AUTOSAR XML (schema 4-0-3)
standard types defined: uint8, Boolean, UInt16, UInt32
package /AUTOSAR_Platform/DataConstrs
  range DC_Boolean: raw 0..1
  range DC_UInt16: raw 0..65535
package /DataTypes/Units
  unit NoUnit1: display-name=NoUnit, factor-si-to-unit=1, offset-si-to-unit=0
package /PATAC/Facility/DataTypes/Implementation
  compu method COMPU_Boolean: 0=FALSE, 1=TRUE
  unit NoUnit: factor-si-to-unit=1, offset-si-to-unit=0
package /PATAC/MSM/ComponentTypes
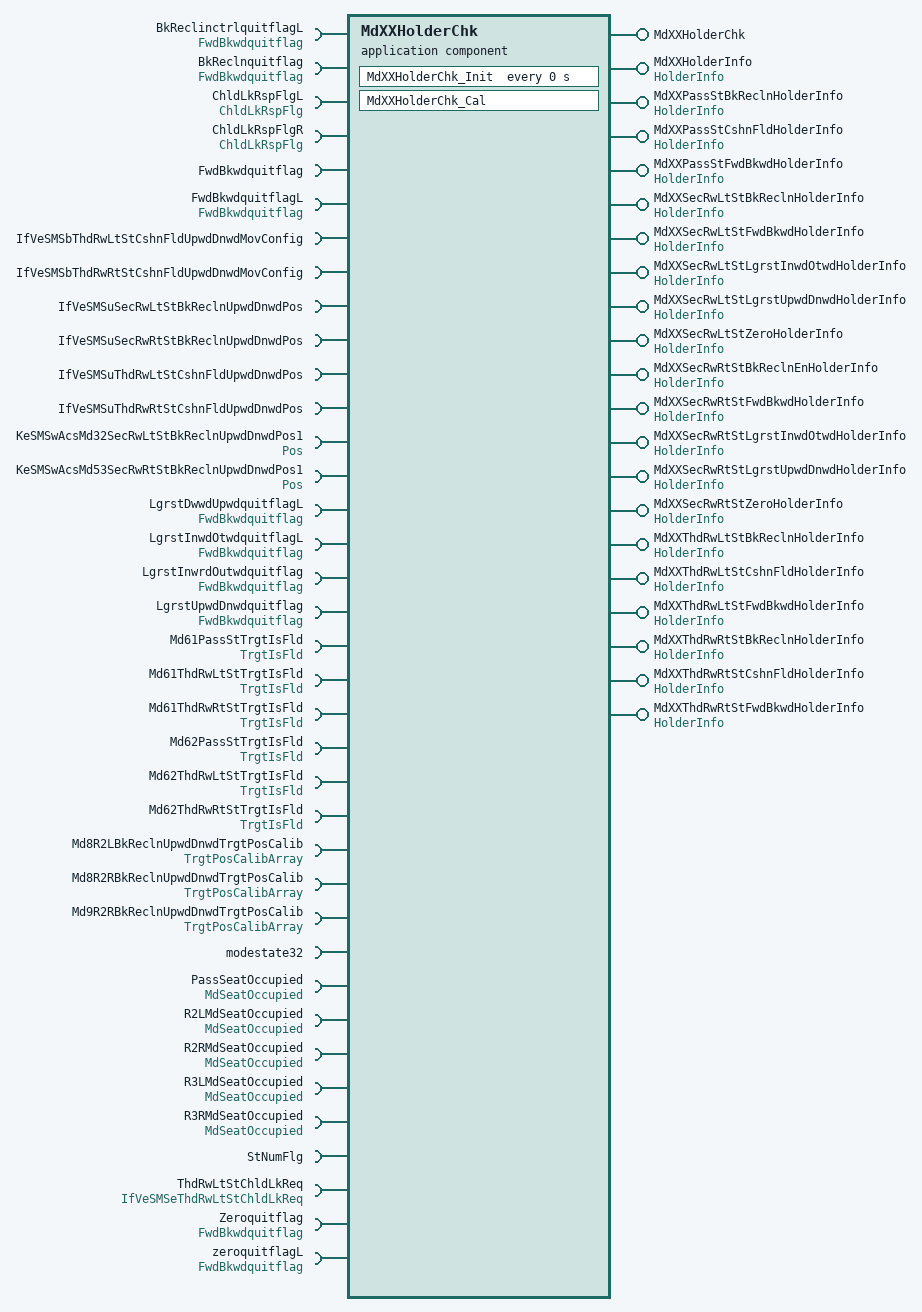
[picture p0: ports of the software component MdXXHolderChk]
  application sw component type MdXXHolderChk
    21 x provide port:
      MdXXHolderChk: server-com-spec{operation=Cal, queue-length=1}, provided-interface=MdXXHolderChk
      MdXXHolderInfo: nonqueued-sender-com-spec{data-element=HolderInfo/Val, init-value=0}, provided-interface=HolderInfo
      MdXXPassStBkReclnHolderInfo: nonqueued-sender-com-spec{data-element=HolderInfo/Val, init-value=0}, provided-interface=HolderInfo
      MdXXPassStCshnFldHolderInfo: nonqueued-sender-com-spec{data-element=HolderInfo/Val, init-value=0}, provided-interface=HolderInfo
      MdXXPassStFwdBkwdHolderInfo: nonqueued-sender-com-spec{data-element=HolderInfo/Val, init-value=0}, provided-interface=HolderInfo
      MdXXSecRwLtStBkReclnHolderInfo: nonqueued-sender-com-spec{data-element=HolderInfo/Val, init-value=0}, provided-interface=HolderInfo
      MdXXSecRwLtStFwdBkwdHolderInfo: nonqueued-sender-com-spec{data-element=HolderInfo/Val, init-value=0}, provided-interface=HolderInfo
      MdXXSecRwLtStLgrstInwdOtwdHolderInfo: nonqueued-sender-com-spec{data-element=HolderInfo/Val, init-value=0}, provided-interface=HolderInfo
      MdXXSecRwLtStLgrstUpwdDnwdHolderInfo: nonqueued-sender-com-spec{data-element=HolderInfo/Val, init-value=0}, provided-interface=HolderInfo
      MdXXSecRwLtStZeroHolderInfo: nonqueued-sender-com-spec{data-element=HolderInfo/Val, init-value=0}, provided-interface=HolderInfo
      MdXXSecRwRtStBkReclnEnHolderInfo: nonqueued-sender-com-spec{data-element=HolderInfo/Val, init-value=0}, provided-interface=HolderInfo
      MdXXSecRwRtStFwdBkwdHolderInfo: nonqueued-sender-com-spec{data-element=HolderInfo/Val, init-value=0}, provided-interface=HolderInfo
      MdXXSecRwRtStLgrstInwdOtwdHolderInfo: nonqueued-sender-com-spec{data-element=HolderInfo/Val, init-value=0}, provided-interface=HolderInfo
      MdXXSecRwRtStLgrstUpwdDnwdHolderInfo: nonqueued-sender-com-spec{data-element=HolderInfo/Val, init-value=0}, provided-interface=HolderInfo
      MdXXSecRwRtStZeroHolderInfo: nonqueued-sender-com-spec{data-element=HolderInfo/Val, init-value=0}, provided-interface=HolderInfo
      MdXXThdRwLtStBkReclnHolderInfo: nonqueued-sender-com-spec{data-element=HolderInfo/Val, init-value=0}, provided-interface=HolderInfo
      MdXXThdRwLtStCshnFldHolderInfo: nonqueued-sender-com-spec{data-element=HolderInfo/Val, init-value=0}, provided-interface=HolderInfo
      MdXXThdRwLtStFwdBkwdHolderInfo: nonqueued-sender-com-spec{data-element=HolderInfo/Val, init-value=0}, provided-interface=HolderInfo
      MdXXThdRwRtStBkReclnHolderInfo: nonqueued-sender-com-spec{data-element=HolderInfo/Val, init-value=0}, provided-interface=HolderInfo
      MdXXThdRwRtStCshnFldHolderInfo: nonqueued-sender-com-spec{data-element=HolderInfo/Val, init-value=0}, provided-interface=HolderInfo
      MdXXThdRwRtStFwdBkwdHolderInfo: nonqueued-sender-com-spec{data-element=HolderInfo/Val, init-value=0}, provided-interface=HolderInfo
    37 x require port:
      BkReclinctrlquitflagL: nonqueued-receiver-com-spec{data-element=FwdBkwdquitflag/Val, filter=data-filter-type=ALWAYS, init-value=0}, required-interface=FwdBkwdquitflag
      BkReclnquitflag: nonqueued-receiver-com-spec{data-element=FwdBkwdquitflag/Val, filter=data-filter-type=ALWAYS, init-value=0}, required-interface=FwdBkwdquitflag
      ChldLkRspFlgL: nonqueued-receiver-com-spec{data-element=ChldLkRspFlg/Val, filter=data-filter-type=ALWAYS, init-value=0}, required-interface=ChldLkRspFlg
      ChldLkRspFlgR: nonqueued-receiver-com-spec{data-element=ChldLkRspFlg/Val, filter=data-filter-type=ALWAYS, init-value=0}, required-interface=ChldLkRspFlg
      FwdBkwdquitflag: nonqueued-receiver-com-spec{data-element=FwdBkwdquitflag/Val, filter=data-filter-type=ALWAYS, init-value=0}, required-interface=FwdBkwdquitflag
      FwdBkwdquitflagL: nonqueued-receiver-com-spec{data-element=FwdBkwdquitflag/Val, filter=data-filter-type=ALWAYS, init-value=0}, required-interface=FwdBkwdquitflag
      IfVeSMSbThdRwLtStCshnFldUpwdDnwdMovConfig: nonqueued-receiver-com-spec{data-element=IfVeSMSbThdRwLtStCshnFldUpwdDnwdMovConfig/Val, filter=data-filter-type=ALWAYS, init-value=0}, required-interface=IfVeSMSbThdRwLtStCshnFldUpwdDnwdMovConfig
      IfVeSMSbThdRwRtStCshnFldUpwdDnwdMovConfig: nonqueued-receiver-com-spec{data-element=IfVeSMSbThdRwRtStCshnFldUpwdDnwdMovConfig/Val, filter=data-filter-type=ALWAYS, init-value=0}, required-interface=IfVeSMSbThdRwRtStCshnFldUpwdDnwdMovConfig
      IfVeSMSuSecRwLtStBkReclnUpwdDnwdPos: nonqueued-receiver-com-spec{data-element=IfVeSMSuSecRwLtStBkReclnUpwdDnwdPos/Val, filter=data-filter-type=ALWAYS, init-value=0}, required-interface=IfVeSMSuSecRwLtStBkReclnUpwdDnwdPos
      IfVeSMSuSecRwRtStBkReclnUpwdDnwdPos: nonqueued-receiver-com-spec{data-element=IfVeSMSuSecRwRtStBkReclnUpwdDnwdPos/Val, filter=data-filter-type=ALWAYS, init-value=0}, required-interface=IfVeSMSuSecRwRtStBkReclnUpwdDnwdPos
      IfVeSMSuThdRwLtStCshnFldUpwdDnwdPos: nonqueued-receiver-com-spec{data-element=IfVeSMSuThdRwLtStCshnFldUpwdDnwdPos/Val, filter=data-filter-type=ALWAYS, init-value=0}, required-interface=IfVeSMSuThdRwLtStCshnFldUpwdDnwdPos
      IfVeSMSuThdRwRtStCshnFldUpwdDnwdPos: nonqueued-receiver-com-spec{data-element=IfVeSMSuThdRwRtStCshnFldUpwdDnwdPos/Val, filter=data-filter-type=ALWAYS, init-value=0}, required-interface=IfVeSMSuThdRwRtStCshnFldUpwdDnwdPos
      KeSMSwAcsMd32SecRwLtStBkReclnUpwdDnwdPos1: parameter-require-com-spec{init-value=0, parameter=Val}, required-interface=Pos
      KeSMSwAcsMd53SecRwRtStBkReclnUpwdDnwdPos1: parameter-require-com-spec{init-value=0, parameter=Val}, required-interface=Pos
      LgrstDwwdUpwdquitflagL: nonqueued-receiver-com-spec{data-element=FwdBkwdquitflag/Val, filter=data-filter-type=ALWAYS, init-value=0}, required-interface=FwdBkwdquitflag
      LgrstInwdOtwdquitflagL: nonqueued-receiver-com-spec{data-element=FwdBkwdquitflag/Val, filter=data-filter-type=ALWAYS, init-value=0}, required-interface=FwdBkwdquitflag
      LgrstInwrdOutwdquitflag: nonqueued-receiver-com-spec{data-element=FwdBkwdquitflag/Val, filter=data-filter-type=ALWAYS, init-value=0}, required-interface=FwdBkwdquitflag
      LgrstUpwdDnwdquitflag: nonqueued-receiver-com-spec{data-element=FwdBkwdquitflag/Val, filter=data-filter-type=ALWAYS, init-value=0}, required-interface=FwdBkwdquitflag
      Md61PassStTrgtIsFld: nonqueued-receiver-com-spec{data-element=TrgtIsFld/Val, filter=data-filter-type=ALWAYS, init-value=0}, required-interface=TrgtIsFld
      Md61ThdRwLtStTrgtIsFld: nonqueued-receiver-com-spec{data-element=TrgtIsFld/Val, filter=data-filter-type=ALWAYS, init-value=0}, required-interface=TrgtIsFld
      Md61ThdRwRtStTrgtIsFld: nonqueued-receiver-com-spec{data-element=TrgtIsFld/Val, filter=data-filter-type=ALWAYS, init-value=0}, required-interface=TrgtIsFld
      Md62PassStTrgtIsFld: nonqueued-receiver-com-spec{data-element=TrgtIsFld/Val, filter=data-filter-type=ALWAYS, init-value=0}, required-interface=TrgtIsFld
      Md62ThdRwLtStTrgtIsFld: nonqueued-receiver-com-spec{data-element=TrgtIsFld/Val, filter=data-filter-type=ALWAYS, init-value=0}, required-interface=TrgtIsFld
      Md62ThdRwRtStTrgtIsFld: nonqueued-receiver-com-spec{data-element=TrgtIsFld/Val, filter=data-filter-type=ALWAYS, init-value=0}, required-interface=TrgtIsFld
      Md8R2LBkReclnUpwdDnwdTrgtPosCalib: nonqueued-receiver-com-spec{data-element=TrgtPosArray, filter=data-filter-type=ALWAYS, init-value=[4095, 4095, 4095]}, required-interface=TrgtPosCalibArray
      Md8R2RBkReclnUpwdDnwdTrgtPosCalib: nonqueued-receiver-com-spec{data-element=TrgtPosArray, filter=data-filter-type=ALWAYS, init-value=[4095, 4095, 4095]}, required-interface=TrgtPosCalibArray
      Md9R2RBkReclnUpwdDnwdTrgtPosCalib: nonqueued-receiver-com-spec{data-element=TrgtPosArray, filter=data-filter-type=ALWAYS, init-value=[4095, 4095, 4095]}, required-interface=TrgtPosCalibArray
      modestate32: nonqueued-receiver-com-spec{data-element=modestate32/Val, filter=data-filter-type=ALWAYS, init-value=0}, required-interface=modestate32
      PassSeatOccupied: nonqueued-receiver-com-spec{data-element=MdSeatOccupied/Val, filter=data-filter-type=ALWAYS, init-value=0}, required-interface=MdSeatOccupied
      R2LMdSeatOccupied: nonqueued-receiver-com-spec{data-element=MdSeatOccupied/Val, filter=data-filter-type=ALWAYS, init-value=0}, required-interface=MdSeatOccupied
      R2RMdSeatOccupied: nonqueued-receiver-com-spec{data-element=MdSeatOccupied/Val, filter=data-filter-type=ALWAYS, init-value=0}, required-interface=MdSeatOccupied
      R3LMdSeatOccupied: nonqueued-receiver-com-spec{data-element=MdSeatOccupied/Val, filter=data-filter-type=ALWAYS, init-value=0}, required-interface=MdSeatOccupied
      R3RMdSeatOccupied: nonqueued-receiver-com-spec{data-element=MdSeatOccupied/Val, filter=data-filter-type=ALWAYS, init-value=0}, required-interface=MdSeatOccupied
      StNumFlg: required-interface=StNumFlg
        required-com-specs:
          data-element=Is4s, filter=data-filter-type=ALWAYS, init-value=0
          data-element=Is6s, filter=data-filter-type=ALWAYS, init-value=0
          data-element=Is6s7s, filter=data-filter-type=ALWAYS, init-value=0
          data-element=Is7s, filter=data-filter-type=ALWAYS, init-value=0
      ThdRwLtStChldLkReq: nonqueued-receiver-com-spec{data-element=IfVeSMSeThdRwLtStChldLkReq/Val, filter=data-filter-type=ALWAYS, init-value=2}, required-interface=IfVeSMSeThdRwLtStChldLkReq
      Zeroquitflag: nonqueued-receiver-com-spec{data-element=FwdBkwdquitflag/Val, filter=data-filter-type=ALWAYS, init-value=0}, required-interface=FwdBkwdquitflag
      zeroquitflagL: nonqueued-receiver-com-spec{data-element=FwdBkwdquitflag/Val, filter=data-filter-type=ALWAYS, init-value=0}, required-interface=FwdBkwdquitflag
    behavior MdXXHolderChk_InternalBehavior
      operation invoked event OIT_MdXXHolderChk_Cal_MdXXHolderChk_Cal: start-on-event=MdXXHolderChk_Cal, operation=MdXXHolderChk.Cal
      timing event MdXXHolderChk_InitEvent: start-on-event=MdXXHolderChk_Init, period=0
      runnable MdXXHolderChk_Cal
        data-receive-point-by-arguments:
          38 x access:
            REC_BkReclinctrlquitflagL_Val: accessed-variable=BkReclinctrlquitflagL.Val
            REC_BkReclnquitflag_Val: accessed-variable=BkReclnquitflag.Val
            REC_ChldLkRspFlgL_Val: accessed-variable=ChldLkRspFlgL.Val
            REC_ChldLkRspFlgR_Val: accessed-variable=ChldLkRspFlgR.Val
            REC_FwdBkwdquitflag_Val: accessed-variable=FwdBkwdquitflag.Val
            REC_FwdBkwdquitflagL_Val: accessed-variable=FwdBkwdquitflagL.Val
            REC_IfVeSMSbThdRwLtStCshnFldUpwdDnwdMovConfig_Val: accessed-variable=IfVeSMSbThdRwLtStCshnFldUpwdDnwdMovConfig.Val
            REC_IfVeSMSbThdRwRtStCshnFldUpwdDnwdMovConfig_Val: accessed-variable=IfVeSMSbThdRwRtStCshnFldUpwdDnwdMovConfig.Val
            REC_IfVeSMSuSecRwLtStBkReclnUpwdDnwdPos_Val: accessed-variable=IfVeSMSuSecRwLtStBkReclnUpwdDnwdPos.Val
            REC_IfVeSMSuSecRwRtStBkReclnUpwdDnwdPos_Val: accessed-variable=IfVeSMSuSecRwRtStBkReclnUpwdDnwdPos.Val
            REC_IfVeSMSuThdRwLtStCshnFldUpwdDnwdPos_Val: accessed-variable=IfVeSMSuThdRwLtStCshnFldUpwdDnwdPos.Val
            REC_IfVeSMSuThdRwRtStCshnFldUpwdDnwdPos_Val: accessed-variable=IfVeSMSuThdRwRtStCshnFldUpwdDnwdPos.Val
            REC_LgrstDwwdUpwdquitflagL_Val: accessed-variable=LgrstDwwdUpwdquitflagL.Val
            REC_LgrstInwdOtwdquitflagL_Val: accessed-variable=LgrstInwdOtwdquitflagL.Val
            REC_LgrstInwrdOutwdquitflag_Val: accessed-variable=LgrstInwrdOutwdquitflag.Val
            REC_LgrstUpwdDnwdquitflag_Val: accessed-variable=LgrstUpwdDnwdquitflag.Val
            REC_Md61PassStTrgtIsFld_Val: accessed-variable=Md61PassStTrgtIsFld.Val
            REC_Md61ThdRwLtStTrgtIsFld_Val: accessed-variable=Md61ThdRwLtStTrgtIsFld.Val
            REC_Md61ThdRwRtStTrgtIsFld_Val: accessed-variable=Md61ThdRwRtStTrgtIsFld.Val
            REC_Md62PassStTrgtIsFld_Val: accessed-variable=Md62PassStTrgtIsFld.Val
            REC_Md62ThdRwLtStTrgtIsFld_Val: accessed-variable=Md62ThdRwLtStTrgtIsFld.Val
            REC_Md62ThdRwRtStTrgtIsFld_Val: accessed-variable=Md62ThdRwRtStTrgtIsFld.Val
            REC_Md8R2LBkReclnUpwdDnwdTrgtPosCalib_TrgtPosArray: accessed-variable=Md8R2LBkReclnUpwdDnwdTrgtPosCalib.TrgtPosArray
            REC_Md8R2RBkReclnUpwdDnwdTrgtPosCalib_TrgtPosArray: accessed-variable=Md8R2RBkReclnUpwdDnwdTrgtPosCalib.TrgtPosArray
            REC_Md9R2RBkReclnUpwdDnwdTrgtPosCalib_TrgtPosArray: accessed-variable=Md9R2RBkReclnUpwdDnwdTrgtPosCalib.TrgtPosArray
            REC_modestate32_Val: accessed-variable=modestate32.Val
            REC_PassSeatOccupied_Val: accessed-variable=PassSeatOccupied.Val
            REC_R2LMdSeatOccupied_Val: accessed-variable=R2LMdSeatOccupied.Val
            REC_R2RMdSeatOccupied_Val: accessed-variable=R2RMdSeatOccupied.Val
            REC_R3LMdSeatOccupied_Val: accessed-variable=R3LMdSeatOccupied.Val
            REC_R3RMdSeatOccupied_Val: accessed-variable=R3RMdSeatOccupied.Val
            REC_StNumFlg_Is4s: accessed-variable=StNumFlg.Is4s
            REC_StNumFlg_Is6s: accessed-variable=StNumFlg.Is6s
            REC_StNumFlg_Is6s7s: accessed-variable=StNumFlg.Is6s7s
            REC_StNumFlg_Is7s: accessed-variable=StNumFlg.Is7s
            REC_ThdRwLtStChldLkReq_Val: accessed-variable=ThdRwLtStChldLkReq.Val
            REC_Zeroquitflag_Val: accessed-variable=Zeroquitflag.Val
            REC_zeroquitflagL_Val: accessed-variable=zeroquitflagL.Val
        data-send-points:
          20 x access:
            SEND_MdXXHolderInfo_Val: accessed-variable=MdXXHolderInfo.Val
            SEND_MdXXPassStBkReclnHolderInfo_Val: accessed-variable=MdXXPassStBkReclnHolderInfo.Val
            SEND_MdXXPassStCshnFldHolderInfo_Val: accessed-variable=MdXXPassStCshnFldHolderInfo.Val
            SEND_MdXXPassStFwdBkwdHolderInfo_Val: accessed-variable=MdXXPassStFwdBkwdHolderInfo.Val
            SEND_MdXXSecRwLtStBkReclnHolderInfo_Val: accessed-variable=MdXXSecRwLtStBkReclnHolderInfo.Val
            SEND_MdXXSecRwLtStFwdBkwdHolderInfo_Val: accessed-variable=MdXXSecRwLtStFwdBkwdHolderInfo.Val
            SEND_MdXXSecRwLtStLgrstInwdOtwdHolderInfo_Val: accessed-variable=MdXXSecRwLtStLgrstInwdOtwdHolderInfo.Val
            SEND_MdXXSecRwLtStLgrstUpwdDnwdHolderInfo_Val: accessed-variable=MdXXSecRwLtStLgrstUpwdDnwdHolderInfo.Val
            SEND_MdXXSecRwLtStZeroHolderInfo_Val: accessed-variable=MdXXSecRwLtStZeroHolderInfo.Val
            SEND_MdXXSecRwRtStBkReclnEnHolderInfo_Val: accessed-variable=MdXXSecRwRtStBkReclnEnHolderInfo.Val
            SEND_MdXXSecRwRtStFwdBkwdHolderInfo_Val: accessed-variable=MdXXSecRwRtStFwdBkwdHolderInfo.Val
            SEND_MdXXSecRwRtStLgrstInwdOtwdHolderInfo_Val: accessed-variable=MdXXSecRwRtStLgrstInwdOtwdHolderInfo.Val
            SEND_MdXXSecRwRtStLgrstUpwdDnwdHolderInfo_Val: accessed-variable=MdXXSecRwRtStLgrstUpwdDnwdHolderInfo.Val
            SEND_MdXXSecRwRtStZeroHolderInfo_Val: accessed-variable=MdXXSecRwRtStZeroHolderInfo.Val
            SEND_MdXXThdRwLtStBkReclnHolderInfo_Val: accessed-variable=MdXXThdRwLtStBkReclnHolderInfo.Val
            SEND_MdXXThdRwLtStCshnFldHolderInfo_Val: accessed-variable=MdXXThdRwLtStCshnFldHolderInfo.Val
            SEND_MdXXThdRwLtStFwdBkwdHolderInfo_Val: accessed-variable=MdXXThdRwLtStFwdBkwdHolderInfo.Val
            SEND_MdXXThdRwRtStBkReclnHolderInfo_Val: accessed-variable=MdXXThdRwRtStBkReclnHolderInfo.Val
            SEND_MdXXThdRwRtStCshnFldHolderInfo_Val: accessed-variable=MdXXThdRwRtStCshnFldHolderInfo.Val
            SEND_MdXXThdRwRtStFwdBkwdHolderInfo_Val: accessed-variable=MdXXThdRwRtStFwdBkwdHolderInfo.Val
        parameter access PA_KeSMSwAcsMd32SecRwLtStBkReclnUpwdDnwdPos1_Val: accessed-parameter=KeSMSwAcsMd32SecRwLtStBkReclnUpwdDnwdPos1.Val
        parameter access PA_KeSMSwAcsMd53SecRwRtStBkReclnUpwdDnwdPos1_Val: accessed-parameter=KeSMSwAcsMd53SecRwRtStBkReclnUpwdDnwdPos1.Val
      runnable MdXXHolderChk_Init
        parameter access PA_KeSMSwAcsMd32SecRwLtStBkReclnUpwdDnwdPos1_Val: accessed-parameter=KeSMSwAcsMd32SecRwLtStBkReclnUpwdDnwdPos1.Val
        parameter access PA_KeSMSwAcsMd53SecRwRtStBkReclnUpwdDnwdPos1_Val: accessed-parameter=KeSMSwAcsMd53SecRwRtStBkReclnUpwdDnwdPos1.Val
  swc implementation MdXXHolderChk_Implementation: behavior=MdXXHolderChk_InternalBehavior
    code-descriptors:
      code Default: artifact-descriptors=autosar-engineering-object={short-label=Default, category=SWSRC}
package /PATAC/MSM/DataTypes
  impl type SeatChldLkSt: category=VALUE, base-type=uint8, compu {0=ChldLkSt_NoActive, 1=ChldLkSt_Lock, 2=ChldLkSt_Unlock}
package /PATAC/MSM/ModeAdjust/CalPortInterface
  parameter interface Pos
    parameter data prototype Val: sw-calibration-access=READ-WRITE, type=UInt16
package /PATAC/MSM/ModeAdjust/DataType
  impl type TrgtPosCalibArray: category=ARRAY, sw-calibration-access=READ-ONLY, type-emitter=RTE  # 0:pos 1:max 2:min
    element Element: array-size=3, array-size-semantics=FIXED-SIZE, implementation-data-type=UInt16, invalid-value=0
package /PATAC/MSM/ModeAdjust/Interfaces
  sender receiver interface IfVeSMSuThdRwLtStCshnFldUpwdDnwdPos: invalidation-policy{data-element=IfVeSMSuThdRwLtStCshnFldUpwdDnwdPos/Val, handle-invalid=DONT-INVALIDATE}
    data Val: type=UInt16
  sender receiver interface IfVeSMSuThdRwRtStCshnFldUpwdDnwdPos: invalidation-policy{data-element=IfVeSMSuThdRwRtStCshnFldUpwdDnwdPos/Val, handle-invalid=DONT-INVALIDATE}
    data Val: type=UInt16
package /PATAC/MSM/ModeAdjust/PortInterface
  client server interface MdXXHolderChk
    operation Cal
  9 x sender receiver interface:
    ChldLkRspFlg: invalidation-policy{data-element=ChldLkRspFlg/Val, handle-invalid=DONT-INVALIDATE}
      data Val: type=Boolean
    FwdBkwdquitflag: invalidation-policy{data-element=FwdBkwdquitflag/Val, handle-invalid=DONT-INVALIDATE}
      data Val: type=Boolean
    HolderInfo: invalidation-policy{data-element=HolderInfo/Val, handle-invalid=DONT-INVALIDATE}
      data Val: type=UInt32
    IfVeSMSeThdRwLtStChldLkReq: invalidation-policy{data-element=IfVeSMSeThdRwLtStChldLkReq/Val, handle-invalid=DONT-INVALIDATE}
      data Val: type=SeatChldLkSt
    MdSeatOccupied: invalidation-policy{data-element=MdSeatOccupied/Val, handle-invalid=DONT-INVALIDATE}
      data Val: type=Boolean
    modestate32: invalidation-policy{data-element=modestate32/Val, handle-invalid=DONT-INVALIDATE}
      data Val: type=UInt32
    StNumFlg
      4 x data, all with type=Boolean:
        Is4s
        Is6s
        Is6s7s
        Is7s
      invalidation-policys:
        data-element=Is4s, handle-invalid=DONT-INVALIDATE
        data-element=Is6s, handle-invalid=DONT-INVALIDATE
        data-element=Is6s7s, handle-invalid=DONT-INVALIDATE
        data-element=Is7s, handle-invalid=DONT-INVALIDATE
    TrgtIsFld: invalidation-policy{data-element=TrgtIsFld/Val, handle-invalid=DONT-INVALIDATE}
      data Val: type=Boolean
    TrgtPosCalibArray: invalidation-policy{data-element=TrgtPosArray, handle-invalid=DONT-INVALIDATE}
      data TrgtPosArray: type=TrgtPosCalibArray  # 0:Pos 1:Max 2:Min
package /PATAC/MSM/PortInterfaces
  4 x sender receiver interface:
    IfVeSMSbThdRwLtStCshnFldUpwdDnwdMovConfig: invalidation-policy{data-element=IfVeSMSbThdRwLtStCshnFldUpwdDnwdMovConfig/Val, handle-invalid=DONT-INVALIDATE}
      data Val: type=Boolean
    IfVeSMSbThdRwRtStCshnFldUpwdDnwdMovConfig: invalidation-policy{data-element=IfVeSMSbThdRwRtStCshnFldUpwdDnwdMovConfig/Val, handle-invalid=DONT-INVALIDATE}
      data Val: type=Boolean
    IfVeSMSuSecRwLtStBkReclnUpwdDnwdPos: invalidation-policy{data-element=IfVeSMSuSecRwLtStBkReclnUpwdDnwdPos/Val, handle-invalid=DONT-INVALIDATE}
      data Val: type=UInt16
    IfVeSMSuSecRwRtStBkReclnUpwdDnwdPos: invalidation-policy{data-element=IfVeSMSuSecRwRtStBkReclnUpwdDnwdPos/Val, handle-invalid=DONT-INVALIDATE}
      data Val: type=UInt16
